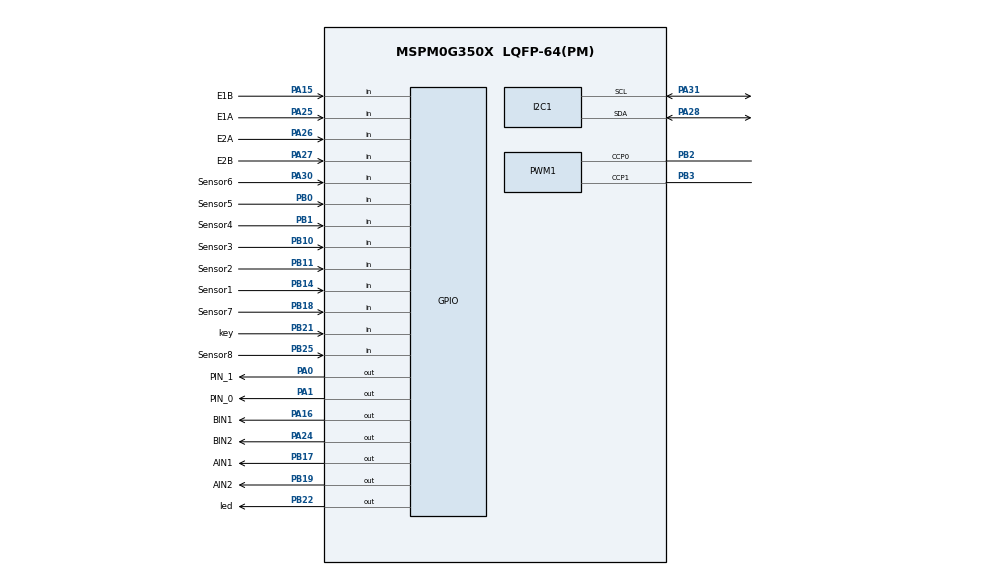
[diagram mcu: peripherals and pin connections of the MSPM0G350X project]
/**
 * @cliArgs --device "MSPM0G350X" --part "Default" --package "LQFP-64(PM)" --product "mspm0_sdk@2.10.00.04"
 * @versions {"tool":"1.26.2+4477"}
 */

/**
 * Import the modules used in this configuration.
 */
const GPIO    = scripting.addModule("/ti/driverlib/GPIO", {}, false);
const GPIO1   = GPIO.addInstance();
const GPIO2   = GPIO.addInstance();
const GPIO3   = GPIO.addInstance();
const GPIO4   = GPIO.addInstance();
const GPIO5   = GPIO.addInstance();
const GPIO6   = GPIO.addInstance();
const GPIO7   = GPIO.addInstance();
const GPIO8   = GPIO.addInstance();
const GPIO9   = GPIO.addInstance();
const I2C     = scripting.addModule("/ti/driverlib/I2C", {}, false);
const I2C1    = I2C.addInstance();
const PWM     = scripting.addModule("/ti/driverlib/PWM", {}, false);
const PWM1    = PWM.addInstance();
const SYSCTL  = scripting.addModule("/ti/driverlib/SYSCTL");
const SYSTICK = scripting.addModule("/ti/driverlib/SYSTICK");
const TIMER   = scripting.addModule("/ti/driverlib/TIMER", {}, false);
const TIMER1  = TIMER.addInstance();

/**
 * Write custom configuration values to the imported modules.
 */
const divider7       = system.clockTree["PLL_PDIV"];
divider7.divideValue = 2;

const divider9       = system.clockTree["UDIV"];
divider9.divideValue = 2;

const gate7  = system.clockTree["MFCLKGATE"];
gate7.enable = true;

const multiplier2         = system.clockTree["PLL_QDIV"];
multiplier2.multiplyValue = 5;

const mux8       = system.clockTree["HSCLKMUX"];
mux8.inputSelect = "HSCLKMUX_SYSPLL2X";

GPIO1.$name                         = "KEY";
GPIO1.associatedPins[0].$name       = "key";
GPIO1.associatedPins[0].direction   = "INPUT";
GPIO1.associatedPins[0].pin.$assign = "PB21";

const Board = scripting.addModule("/ti/driverlib/Board", {}, false);

GPIO2.$name                         = "LED";
GPIO2.associatedPins[0].$name       = "led";
GPIO2.associatedPins[0].pin.$assign = "PB22";

GPIO3.port                          = "PORTA";
GPIO3.$name                         = "BIN";
GPIO3.associatedPins.create(2);
GPIO3.associatedPins[0].$name       = "BIN1";
GPIO3.associatedPins[0].pin.$assign = "PA16";
GPIO3.associatedPins[1].$name       = "BIN2";
GPIO3.associatedPins[1].pin.$assign = "PA24";

GPIO4.$name                         = "AIN";
GPIO4.port                          = "PORTB";
GPIO4.associatedPins.create(2);
GPIO4.associatedPins[0].$name       = "AIN1";
GPIO4.associatedPins[0].pin.$assign = "PB17";
GPIO4.associatedPins[1].$name       = "AIN2";
GPIO4.associatedPins[1].pin.$assign = "PB19";

GPIO5.$name                               = "ENCODERA";
GPIO5.associatedPins.create(2);
GPIO5.associatedPins[0].$name             = "E1A";
GPIO5.associatedPins[0].direction         = "INPUT";
GPIO5.associatedPins[0].polarity          = "RISE";
GPIO5.associatedPins[0].interruptPriority = "0";
GPIO5.associatedPins[0].interruptEn       = true;
GPIO5.associatedPins[0].pin.$assign       = "PA25";
GPIO5.associatedPins[1].$name             = "E1B";
GPIO5.associatedPins[1].direction         = "INPUT";
GPIO5.associatedPins[1].polarity          = "RISE";
GPIO5.associatedPins[1].interruptPriority = "0";
GPIO5.associatedPins[1].interruptEn       = true;
GPIO5.associatedPins[1].pin.$assign       = "PA15";

GPIO6.$name                               = "ENCODERB";
GPIO6.port                                = "PORTA";
GPIO6.associatedPins.create(2);
GPIO6.associatedPins[0].$name             = "E2A";
GPIO6.associatedPins[0].direction         = "INPUT";
GPIO6.associatedPins[0].polarity          = "RISE";
GPIO6.associatedPins[0].interruptPriority = "0";
GPIO6.associatedPins[0].interruptEn       = true;
GPIO6.associatedPins[0].pin.$assign       = "PA26";
GPIO6.associatedPins[1].$name             = "E2B";
GPIO6.associatedPins[1].direction         = "INPUT";
GPIO6.associatedPins[1].polarity          = "RISE";
GPIO6.associatedPins[1].interruptPriority = "0";
GPIO6.associatedPins[1].interruptEn       = true;
GPIO6.associatedPins[1].pin.$assign       = "PA27";

GPIO7.port                          = "PORTA";
GPIO7.$name                         = "MPU6050_SCL";
GPIO7.associatedPins[0].$name       = "PIN_0";
GPIO7.associatedPins[0].pin.$assign = "PA1";

GPIO8.$name                          = "MPU6050_SDA";
GPIO8.associatedPins[0].$name        = "PIN_1";
GPIO8.associatedPins[0].assignedPort = "PORTA";
GPIO8.associatedPins[0].pin.$assign  = "PA0";

GPIO9.$name                         = "Sensor";
GPIO9.associatedPins.create(8);
GPIO9.associatedPins[0].$name       = "Sensor1";
GPIO9.associatedPins[0].direction   = "INPUT";
GPIO9.associatedPins[0].ioStructure = "SD";
GPIO9.associatedPins[0].pin.$assign = "PB14";
GPIO9.associatedPins[1].$name       = "Sensor2";
GPIO9.associatedPins[1].direction   = "INPUT";
GPIO9.associatedPins[1].ioStructure = "SD";
GPIO9.associatedPins[1].pin.$assign = "PB11";
GPIO9.associatedPins[2].$name       = "Sensor3";
GPIO9.associatedPins[2].direction   = "INPUT";
GPIO9.associatedPins[2].ioStructure = "SD";
GPIO9.associatedPins[2].pin.$assign = "PB10";
GPIO9.associatedPins[3].$name       = "Sensor4";
GPIO9.associatedPins[3].direction   = "INPUT";
GPIO9.associatedPins[3].pin.$assign = "PB1";
GPIO9.associatedPins[4].$name       = "Sensor5";
GPIO9.associatedPins[4].direction   = "INPUT";
GPIO9.associatedPins[4].pin.$assign = "PB0";
GPIO9.associatedPins[5].$name       = "Sensor6";
GPIO9.associatedPins[5].direction   = "INPUT";
GPIO9.associatedPins[5].pin.$assign = "PA30";
GPIO9.associatedPins[6].$name       = "Sensor7";
GPIO9.associatedPins[6].direction   = "INPUT";
GPIO9.associatedPins[6].pin.$assign = "PB18";
GPIO9.associatedPins[7].$name       = "Sensor8";
GPIO9.associatedPins[7].direction   = "INPUT";
GPIO9.associatedPins[7].pin.$assign = "PB25";

I2C1.$name                             = "OLED";
I2C1.profile                           = "CONFIG_PROFILE_1";
I2C1.peripheral.$assign                = "I2C0";
I2C1.peripheral.sdaPin.$assign         = "PA28";
I2C1.peripheral.sclPin.$assign         = "PA31";
I2C1.sdaPinConfig.$name                = "ti_driverlib_gpio_GPIOPinGeneric0";
I2C1.sdaPinConfig.hideOutputInversion  = scripting.forceWrite(false);
I2C1.sdaPinConfig.onlyInternalResistor = scripting.forceWrite(false);
I2C1.sdaPinConfig.passedPeripheralType = scripting.forceWrite("Digital");
I2C1.sclPinConfig.$name                = "ti_driverlib_gpio_GPIOPinGeneric1";
I2C1.sclPinConfig.hideOutputInversion  = scripting.forceWrite(false);
I2C1.sclPinConfig.onlyInternalResistor = scripting.forceWrite(false);
I2C1.sclPinConfig.passedPeripheralType = scripting.forceWrite("Digital");

PWM1.$name                      = "PWM_0";
PWM1.timerStartTimer            = true;
PWM1.pwmMode                    = "EDGE_ALIGN_UP";
PWM1.timerCount                 = 8000;
PWM1.peripheral.$assign         = "TIMA1";
PWM1.peripheral.ccp0Pin.$assign = "PB2";
PWM1.peripheral.ccp1Pin.$assign = "PB3";
PWM1.PWM_CHANNEL_0.$name        = "ti_driverlib_pwm_PWMTimerCC0";
PWM1.PWM_CHANNEL_1.$name        = "ti_driverlib_pwm_PWMTimerCC1";
PWM1.ccp0PinConfig.$name        = "ti_driverlib_gpio_GPIOPinGeneric4";
PWM1.ccp1PinConfig.$name        = "ti_driverlib_gpio_GPIOPinGeneric5";

SYSCTL.forceDefaultClkConfig = true;
SYSCTL.clockTreeEn           = true;

SYSTICK.periodEnable  = true;
SYSTICK.systickEnable = true;
SYSTICK.period        = 16777216;

TIMER1.$name              = "TIMER_0";
TIMER1.timerClkPrescale   = 32;
TIMER1.timerMode          = "PERIODIC";
TIMER1.timerStartTimer    = true;
TIMER1.interrupts         = ["ZERO"];
TIMER1.timerPeriod        = "10 ms";
TIMER1.peripheral.$assign = "TIMG0";

/**
 * Pinmux solution for unlocked pins/peripherals. This ensures that minor changes to the automatic solver in a future
 * version of the tool will not impact the pinmux you originally saw.  These lines can be completely deleted in order to
 * re-solve from scratch.
 */
Board.peripheral.$suggestSolution          = "DEBUGSS";
Board.peripheral.swclkPin.$suggestSolution = "PA20";
Board.peripheral.swdioPin.$suggestSolution = "PA19";
